# FM33G0XX register map
File version: 1.0
CPU: SC000 r1p0, little endian, no MPU, no FPU, 3 interrupt priority bits
Registers are 32-bit, read-write, reset 0x0 unless marked. A register's access mark holds for its fields unless they carry their own. Offsets are from the block's base; [hi:lo] are bit positions; {n}, {i} and the like mark numbered series; 'fields as' and 'values as' point back to an identical list.

## NVMIF — NVMIF Registers
Base 0x40001000
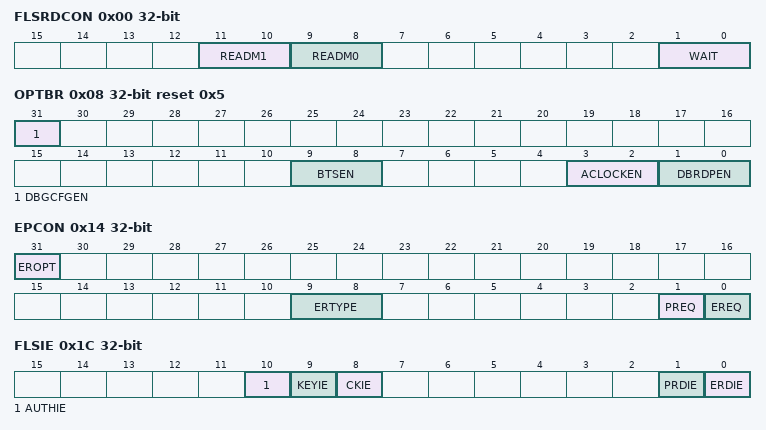
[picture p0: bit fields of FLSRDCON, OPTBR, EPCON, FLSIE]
0x00 FLSRDCON — FLASH read control register
  [11:10] READM1 — ERASE Margin Read
    0=DISABLE (DISABLE Margin Read); 1=DISABLE (DISABLE Margin Read); 2=ENABLE (ENABLE Margin Read); 3=DISABLE (DISABLE Margin Read)
  [9:8] READM0 — PROG Margin Read
    values as READM1
  [1:0] WAIT — wait cycle at flash resd
    0=ZERO (0 wait cycle); 1=ONE (1 wait cycle); 2=TWO (2 wait cycle); 3=ZERO (0 wait cycle)
0x04 PRFTCON — PREFATCH CONTROL REGISTER
  [0] DUMMY
0x08 OPTBR ro reset 0x5
  [31] DBGCFGEN — DEBUG CONFIG REGISTER ENABLE
    0=DISABLE (DEBUG CONFIG REGISTER DISABLE); 1=ENABLE (DEBUG CONFIG REGISTER ENABLE)
  [9:8] BTSEN — BootSwap Enable
    0=DISABLE; 1=DISABLE; 2=ENABLE; 3=DISABLE
  [3:2] ACLOCKEN
    0=DISABLE (ACLOCK DISABLE); 1=DISABLE (ACLOCK DISABLE); 2=ENABLE (ACLOCK ENABLE); 3=DISABLE (ACLOCK DISABLE)
  [1:0] DBRDPEN — debug port read protect
    0=DISABLE (debug port read protect disable); 1=DISABLE (debug port read protect disable); 2=ENABLE (debug port read protect enable); 3=DISABLE (debug port read protect disable)
0x0C ACLOCK1 — ACLOCK config reister1
0x14 EPCON — erase & prog config register
  [31] EROPT — HOLD CPU AT ERASE AND PROG
  [9:8] ERTYPE — erase tyre
    0=SECTOR (Sector Erase); 1=BLOCK (Block Erase); 2=CHIP (Chip Erase); 3=SECTOR (Sector Erase)
  [1] PREQ wo — Program Request
  [0] EREQ write_only — Erase Request
0x18 FLSKEY — FLASH KEY REGISTER
0x1C FLSIE — FLASH IE
  [10] AUTHIE — AUTH ERR IE
  [9] KEYIE — FLASH KEY ERR IE
  [8] CKIE — CLOCK ERR IE
  [1] PRDIE — PROG FINISH IE
  [0] ERDIE — ERASE FINISH IE
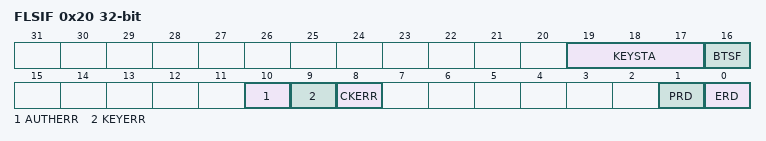
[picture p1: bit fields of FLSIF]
0x20 FLSIF — FLASH IF
  [19:17] KEYSTA ro — KEY STATE
    0=IDLE; 1=CHIP_ERASE_UNLOCK; 2=SECTOR_ERASE_UNLOCK; 3=PROG_UNLOCK; 4=KEY_ERR
  [16] BTSF ro — BootSwap FLAG
    0=BOOT_0000H; 1=BOOT_2000H
  [10] AUTHERR — AUTH ERR IF
  [9] KEYERR — KEY ERR IF
  [8] CKERR — CLK ERR IF
  [1] PRD — PROG DONE IF
  [0] ERD — ERASE DONE IF

## CRC
Base 0x40010000
0x00 CRCDR reset 0xFF — CRC DATA REGISTER
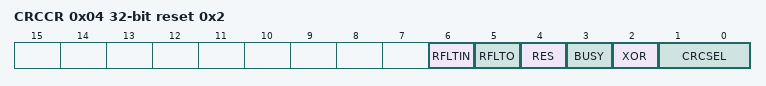
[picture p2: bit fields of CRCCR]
0x04 CRCCR reset 0x2 — CRC CONTROL REGISTER
  [6] RFLTIN — input reverse
  [5] RFLTO — output reverse
  [4] RES ro — result is zero
  [3] BUSY ro
  [2] XOR — OUTPUT XOR
  [1:0] CRCSEL — MODE SELECT
    0=CRC16; 1=CRC8; 2=CCITT; 3=CCITT
0x08 CRCLFSR
  [15:0] LFSR
0x0C CRC_XOR
  [15:0] CRCXOR
0x10 FLSCRCEN — FLASH CRC ENABLE
  [0] FLSCRCEN
0x14 CRCFLSAD — FLASH CRC ADDR
  [16:0] FLSAD
0x18 CRCFLSSIZE — FLASH CRC SIZE
  [16:0] FLSS — SIZE = (FLSS+1)*4

## DISP — DISP Registers
Base 0x40010C00
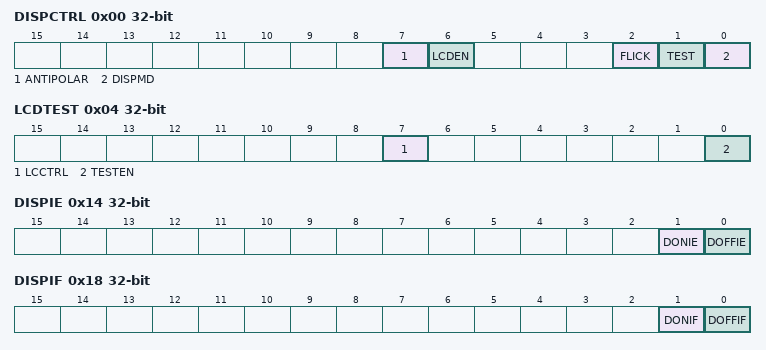
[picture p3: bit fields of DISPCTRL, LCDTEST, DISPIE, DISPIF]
0x00 DISPCTRL — GPIO EXTI Select 0
  [7] ANTIPOLAR — COM & SEG C0ONNECT TO GND OR FLOATING AT DISP DISABLE
    0=FLOATING; 1=GND
  [6] LCDEN — lcd enable
    0=DISABLE; 1=ENABLE
  [2] FLICK — FLICK ENABLE
  [1] TEST — OUTPUT MODE AT TEST
    0=OFF; 1=ON
  [0] DISPMD — DISP MODE
    0=NORMAL (NORMAL MODE); 1=TEST (TEST MODE)
0x04 LCDTEST
  [7] LCCTRL — TEST CONTROL
  [0] TESTEN — EXTI1[0] input pin select
0x08 DF — DIVIDED FREQ
  [7:0] DF
0x0C TON — FLICK TIME SETTING
  [7:0] TON
0x10 TOFF — FLICK TIME SETTING
  [7:0] TOFF
0x14 DISPIE
  [1] DONIE — DISPLAY ON IE
  [0] DOFFIE — DISPLAY OFF IE
0x18 DISPIF
  [1] DONIF — DISP ON IF
  [0] DOFFIF — DISP OFF IF
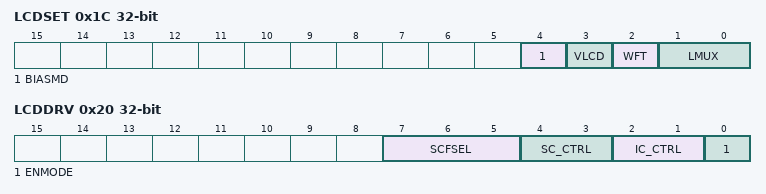
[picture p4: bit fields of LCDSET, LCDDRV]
0x1C LCDSET — LCD SETTING register
  [4] BIASMD — BIAS MODE SELECT
    0=1/4BIAS; 1=1/3BIAS
  [3] VLCD — VLCD SELECT
    0=INNER; 1=OUTER
  [2] WFT — TYPE SELECT
    0=TYPEA (TAPEA); 1=TYPEB
  [1:0] LMUX — COM SELECT
    0=4COM; 1=6COM; 2=8COM; 3=8COM
0x20 LCDDRV — LCD DRIVE SETTING
  [7:5] SCFSEL — SC FREQ SELECT
  [4:3] SC_CTRL — OUTTER CAP DRIVE MODE
  [2:1] IC_CTRL — BIAS CURRENT SEETING
  [0] ENMODE — DRIVE MODE
    0=CAP (OUTTER CAP); 1=RBUF (INNER RES BUFF)
{0x24+4i} DISPDATA{i} (i=0..9) — DISPLAY DATA REGISTER
0x4C LCDBIAS reset 0xE — LCD BIAS SETTING
  [3:0] LCDBIAS
0x50 COM_EN — COM ENABLE
  [3:0] COMEN — COMEN 0-3
0x54 SEG_EN0 — SEG ENABLE
  [31:0] SEGEN
0x58 SEG_EN1 — SEG ENABLE
  [11:0] SEGEN
